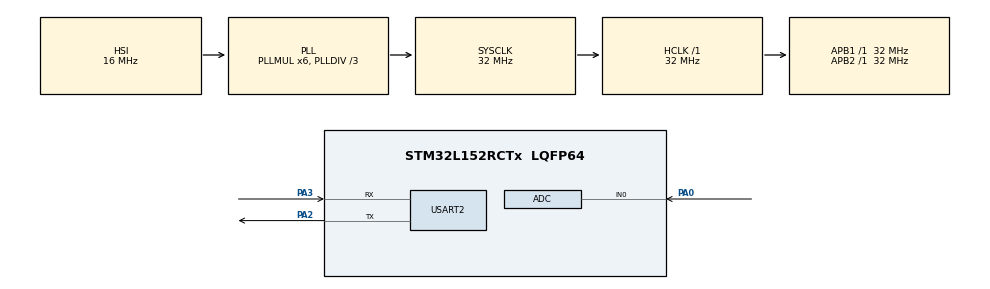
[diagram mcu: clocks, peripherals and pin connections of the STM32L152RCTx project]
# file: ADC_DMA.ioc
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ADC.Channel-1\#ChannelRegularConversion=ADC_CHANNEL_0
ADC.ContinuousConvMode=ENABLE
ADC.NbrOfConversionFlag=1
ADC.Rank-1\#ChannelRegularConversion=1
ADC.SamplingTime-1\#ChannelRegularConversion=ADC_SAMPLETIME_4CYCLES
Dma.ADC.0.Direction=DMA_PERIPH_TO_MEMORY
Dma.ADC.0.Instance=DMA1_Channel1
Dma.ADC.0.MemDataAlignment=DMA_MDATAALIGN_HALFWORD
Dma.ADC.0.MemInc=DMA_MINC_ENABLE
Dma.ADC.0.Mode=DMA_CIRCULAR
Dma.ADC.0.PeriphDataAlignment=DMA_PDATAALIGN_WORD
Dma.ADC.0.PeriphInc=DMA_PINC_DISABLE
Dma.ADC.0.Priority=DMA_PRIORITY_LOW
Dma.Request0=ADC
Mcu.Family=STM32L1
Mcu.Name=STM32L152RCTx
Mcu.Package=LQFP64
NVIC.DMA1_Channel1_IRQn=true\:0\:0\:false\:false\:true\:false\:true\:true
NVIC.PriorityGroup=NVIC_PRIORITYGROUP_0
PA0-WKUP1.Mode=IN0
PA0-WKUP1.Signal=ADC_IN0
PA2.Mode=Asynchronous
PA2.Signal=USART2_TX
PA3.Mode=Asynchronous
PA3.Signal=USART2_RX
ProjectManager.HeapSize=0x200
ProjectManager.StackSize=0x400
ProjectManager.TargetToolchain=STM32CubeIDE
RCC.48MHZClocksFreq_Value=48000000
RCC.AHBFreq_Value=32000000
RCC.APB1Freq_Value=32000000
RCC.APB1TimFreq_Value=32000000
RCC.APB2Freq_Value=32000000
RCC.APB2TimFreq_Value=32000000
RCC.HCLKFreq_Value=32000000
RCC.HSE_VALUE=8000000
RCC.HSI_VALUE=16000000
RCC.LSE_VALUE=32768
RCC.MSI_VALUE=2097000
RCC.PLLDIV=RCC_PLL_DIV3
RCC.PLLMUL=RCC_PLL_MUL6
RCC.RTCClockSelectionVirtual=RCC_RTCCLKSOURCE_LSE
RCC.SYSCLKFreq_VALUE=32000000
RCC.SYSCLKSource=RCC_SYSCLKSOURCE_PLLCLK
RCC.USBOutput=48000000
RCC.VCOOutputFreq_Value=96000000
USART2.VirtualMode=VM_ASYNC
board=STM32L152C-DISCO

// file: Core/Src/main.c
/* USER CODE BEGIN Header */
/**
  ******************************************************************************
  * @file           : main.c
  * @brief          : Main program body
  ******************************************************************************
  * @attention
  *
  * Copyright (c) 2023 STMicroelectronics.
  * All rights reserved.
  *
  * This software is licensed under terms that can be found in the LICENSE file
  * in the root directory of this software component.
  * If no LICENSE file comes with this software, it is provided AS-IS.
  *
  ******************************************************************************
  */
/* USER CODE END Header */
#include "main.h"

ADC_HandleTypeDef hadc;
DMA_HandleTypeDef hdma_adc;

UART_HandleTypeDef huart2;

/* USER CODE BEGIN PV */
uint32_t adc_val;
uint32_t buffer;
/* USER CODE END PV */

void SystemClock_Config(void);
static void MX_GPIO_Init(void);
static void MX_DMA_Init(void);
static void MX_ADC_Init(void);
static void MX_USART2_UART_Init(void);

/* USER CODE BEGIN 0 */
void HAL_ADC_ConvCpltCallback(ADC_HandleTypeDef* hadc)
{
	adc_val=buffer;
	//HAL_GPIO_TogglePin(BSP_LED1_GPIO_Port, BSP_LED1_Pin);

	printf("%d\n",buffer);

	//HAL_ADC_Start_DMA(&hadc,&buffer,1);

}
/* USER CODE END 0 */

int main(void)
{

  /* MCU Configuration--------------------------------------------------------*/

  /* Reset of all peripherals, Initializes the Flash interface and the Systick. */
  HAL_Init();

  /* Configure the system clock */
  SystemClock_Config();

  /* Initialize all configured peripherals */
  MX_GPIO_Init();
  MX_DMA_Init();
  MX_ADC_Init();
  MX_USART2_UART_Init();
  /* USER CODE BEGIN 2 */
  HAL_ADC_Start_DMA(&hadc,&buffer,sizeof(buffer));
  /* USER CODE END 2 */

  /* Infinite loop */
  while (1)
  {

  }
}

void SystemClock_Config(void)
{
  RCC_OscInitTypeDef RCC_OscInitStruct = {0};
  RCC_ClkInitTypeDef RCC_ClkInitStruct = {0};

  /** Configure the main internal regulator output voltage
  */
  __HAL_PWR_VOLTAGESCALING_CONFIG(PWR_REGULATOR_VOLTAGE_SCALE1);

  /** Initializes the RCC Oscillators according to the specified parameters
  * in the RCC_OscInitTypeDef structure.
  */
  RCC_OscInitStruct.OscillatorType = RCC_OSCILLATORTYPE_HSI;
  RCC_OscInitStruct.HSIState = RCC_HSI_ON;
  RCC_OscInitStruct.HSICalibrationValue = RCC_HSICALIBRATION_DEFAULT;
  RCC_OscInitStruct.PLL.PLLState = RCC_PLL_ON;
  RCC_OscInitStruct.PLL.PLLSource = RCC_PLLSOURCE_HSI;
  RCC_OscInitStruct.PLL.PLLMUL = RCC_PLL_MUL6;
  RCC_OscInitStruct.PLL.PLLDIV = RCC_PLL_DIV3;
  if (HAL_RCC_OscConfig(&RCC_OscInitStruct) != HAL_OK)
  {
    Error_Handler();
  }

  /** Initializes the CPU, AHB and APB buses clocks
  */
  RCC_ClkInitStruct.ClockType = RCC_CLOCKTYPE_HCLK|RCC_CLOCKTYPE_SYSCLK
                              |RCC_CLOCKTYPE_PCLK1|RCC_CLOCKTYPE_PCLK2;
  RCC_ClkInitStruct.SYSCLKSource = RCC_SYSCLKSOURCE_PLLCLK;
  RCC_ClkInitStruct.AHBCLKDivider = RCC_SYSCLK_DIV1;
  RCC_ClkInitStruct.APB1CLKDivider = RCC_HCLK_DIV1;
  RCC_ClkInitStruct.APB2CLKDivider = RCC_HCLK_DIV1;

  if (HAL_RCC_ClockConfig(&RCC_ClkInitStruct, FLASH_LATENCY_1) != HAL_OK)
  {
    Error_Handler();
  }
}

static void MX_ADC_Init(void)
{

  ADC_ChannelConfTypeDef sConfig = {0};

  /** Configure the global features of the ADC (Clock, Resolution, Data Alignment and number of conversion)
  */
  hadc.Instance = ADC1;
  hadc.Init.ClockPrescaler = ADC_CLOCK_ASYNC_DIV1;
  hadc.Init.Resolution = ADC_RESOLUTION_12B;
  hadc.Init.DataAlign = ADC_DATAALIGN_RIGHT;
  hadc.Init.ScanConvMode = ADC_SCAN_DISABLE;
  hadc.Init.EOCSelection = ADC_EOC_SEQ_CONV;
  hadc.Init.LowPowerAutoWait = ADC_AUTOWAIT_DISABLE;
  hadc.Init.LowPowerAutoPowerOff = ADC_AUTOPOWEROFF_DISABLE;
  hadc.Init.ChannelsBank = ADC_CHANNELS_BANK_A;
  hadc.Init.ContinuousConvMode = ENABLE;
  hadc.Init.NbrOfConversion = 1;
  hadc.Init.DiscontinuousConvMode = DISABLE;
  hadc.Init.ExternalTrigConv = ADC_SOFTWARE_START;
  hadc.Init.ExternalTrigConvEdge = ADC_EXTERNALTRIGCONVEDGE_NONE;
  hadc.Init.DMAContinuousRequests = DISABLE;
  if (HAL_ADC_Init(&hadc) != HAL_OK)
  {
    Error_Handler();
  }

  /** Configure for the selected ADC regular channel its corresponding rank in the sequencer and its sample time.
  */
  sConfig.Channel = ADC_CHANNEL_0;
  sConfig.Rank = ADC_REGULAR_RANK_1;
  sConfig.SamplingTime = ADC_SAMPLETIME_4CYCLES;
  if (HAL_ADC_ConfigChannel(&hadc, &sConfig) != HAL_OK)
  {
    Error_Handler();
  }

}

static void MX_USART2_UART_Init(void)
{

  huart2.Instance = USART2;
  huart2.Init.BaudRate = 115200;
  huart2.Init.WordLength = UART_WORDLENGTH_8B;
  huart2.Init.StopBits = UART_STOPBITS_1;
  huart2.Init.Parity = UART_PARITY_NONE;
  huart2.Init.Mode = UART_MODE_TX_RX;
  huart2.Init.HwFlowCtl = UART_HWCONTROL_NONE;
  huart2.Init.OverSampling = UART_OVERSAMPLING_16;
  if (HAL_UART_Init(&huart2) != HAL_OK)
  {
    Error_Handler();
  }

}

static void MX_DMA_Init(void)
{

  /* DMA controller clock enable */
  __HAL_RCC_DMA1_CLK_ENABLE();

  /* DMA interrupt init */
  /* DMA1_Channel1_IRQn interrupt configuration */
  HAL_NVIC_SetPriority(DMA1_Channel1_IRQn, 0, 0);
  HAL_NVIC_EnableIRQ(DMA1_Channel1_IRQn);

}

static void MX_GPIO_Init(void)
{

  /* GPIO Ports Clock Enable */
  __HAL_RCC_GPIOA_CLK_ENABLE();

}

void Error_Handler(void)
{
  __disable_irq();
  while (1)
  {
  }
}
